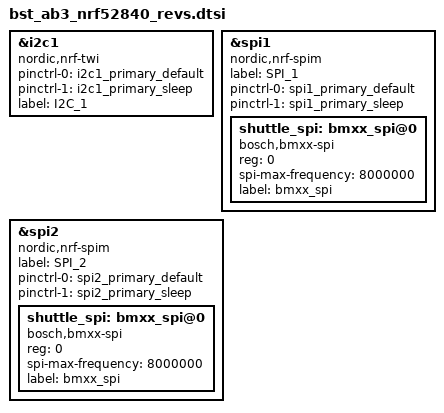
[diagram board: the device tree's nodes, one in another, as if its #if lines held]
/*
 * Copyright (c) 2022 Bosch Sensortec GmbH
 *
 * SPDX-License-Identifier: Apache-2.0
 *
 * Common file for all revisions of DTS for Bosch Sensortec Application Board 3.0
 * This file contains all the variations in one place, and different sections are
 * activated in the corresponding revision overlays.
 *
 * Below is the revision table for reference. Refer the note on Revisions 
 * in bst_ab3_nrf52840.dts for further details.
 * Rev No.		i2c1 					spi1 				spi2
 *  1		primary_i2c_port		disabled			primary_spi_port [DEFAULT]
 *  2		primary_i2c_port		disabled			aux_spi_port	
 *  3		aux_i2c_port			disabled			primary_spi_port	
 *  4		disabled				primary_spi_port	aux_spi_port
 */
#include "bst_ab3_nrf52840-pinctrl.dtsi"

#if defined(BST_AB3_REV1)
	#define I2C1_PRIMARY
	#define SPI1_DISABLED
	#define SPI2_PRIMARY
#elif defined(BST_AB3_REV2)
	#define I2C1_PRIMARY
	#define SPI1_DISABLED
	#define SPI2_AUX
#elif defined(BST_AB3_REV3)
	#define I2C1_AUX
	#define SPI1_DISABLED
	#define SPI2_PRIMARY
#elif defined(BST_AB3_REV4)
	#define I2C1_DISABLED
	#define SPI1_PRIMARY
	#define SPI2_AUX
#else
	#error Unknown BST AB3 Revision	
#endif

#if defined(I2C1_PRIMARY)
	/*i2c1 is used as primary shuttle i2c port*/
	shuttle_i2c: &i2c1 {
		compatible = "nordic,nrf-twi";
		status = "okay";
		//sda-pin = <6>; 
		//scl-pin = <16>;
		pinctrl-0 = <&i2c1_primary_default>;
		pinctrl-1 = <&i2c1_primary_sleep>;
		pinctrl-names = "default", "sleep";
		label = "I2C_1";
	};
#elif defined(I2C1_AUX)
	/*i2c1 is used for auxilliary shuttle i2c port*/
	shuttle_aux_i2c: &i2c1 {
		compatible = "nordic,nrf-twi";
		status = "okay";
		//sda-pin = <13>;  /*GPIO 1 acts as aux i2c SDA*/
		//scl-pin = <14>;  /*GPIO 0 acts as aux i2c SCL*/
		pinctrl-0 = <&i2c1_aux_default>;
		pinctrl-1 = <&i2c1_aux_sleep>;
		label = "I2C_1";
	};
#elif defined(I2C1_DISABLED)
	/*i2c1 is disabled*/
	&i2c1 {
			status = "disabled";
		};
#endif

#if defined(SPI1_PRIMARY)
	/*spi1 is used as primary shuttle spi port*/
	&spi1 {
		compatible = "nordic,nrf-spim";
		status = "okay";
		label = "SPI_1";
		//sck-pin = <16>;
		//mosi-pin = <6>;
		//miso-pin = <15>;
		pinctrl-0 = <&spi1_primary_default>;
		pinctrl-1 = <&spi1_primary_sleep>;
		pinctrl-names = "default", "sleep";
		/*cs-gpios   = <&gpio0 24 GPIO_ACTIVE_LOW>;*/
		/*CS gpio pin is not defined in DTS, as it can be potentially a 
		different pin from the default for some sensors*/
		/*bmxx_spi represents the primary SPI interface of a BST sensor chip mounted on 
		the shuttle board*/
		shuttle_spi: bmxx_spi@0 {
			compatible = "bosch,bmxx-spi";
			reg = <0>;
			spi-max-frequency = <8000000>;
			label = "bmxx_spi";
			status = "okay";
		};

	};
#elif defined(SPI1_DISABLED)
	/*spi1 is disabled*/
	&spi1 {
		status = "disabled";
		label = "SPI_1";
	};
#endif

#if defined(SPI2_PRIMARY)
	/*spi2 is used as primary shuttle spi port*/
	&spi2 {
		compatible = "nordic,nrf-spim";
		status = "okay";
		label = "SPI_2";
		//sck-pin = <16>;
		//mosi-pin = <6>;
		//miso-pin = <15>;
		pinctrl-0 = <&spi2_primary_default>;
		pinctrl-1 = <&spi2_primary_sleep>;
		pinctrl-names = "default", "sleep";
		/*cs-gpios   = <&gpio0 24 GPIO_ACTIVE_LOW>;*/
		/*CS gpio pin is not defined in DTS, as it can be potentially a 
		different pin from the default for some sensors*/
		/*bmxx_spi represents the primary SPI interface of a BST sensor chip mounted on 
		the shuttle board*/
		shuttle_spi: bmxx_spi@0 {
			compatible = "bosch,bmxx-spi";
			reg = <0>;
			spi-max-frequency = <8000000>;
			label = "bmxx_spi";
			status = "okay";
		};
	};
#elif defined(SPI2_AUX)
	/*spi2 is used as auxilliary shuttle spi port*/
	&spi2 {
		compatible = "nordic,nrf-spim";
		status = "okay";
		label = "SPI_2";
		//sck-pin = <34>;  /*P1.02*/
		//mosi-pin = <42>; /*P1.10*/
		//miso-pin = <43>; /*P1.11*/
		pinctrl-0 = <&spi2_aux_default>;
		pinctrl-1 = <&spi2_aux_sleep>;
		pinctrl-names = "default", "sleep";

		/*cs-gpios   = <&gpio1 3 GPIO_ACTIVE_LOW>;*/
		/*CS gpio pin is not defined in DTS, as it can be potentially a 
		different pin from the default for some sensors*/
		/*bmxx_spi represents the auxiliary SPI interface of a BST sensor chip mounted on 
		the shuttle board*/
		shuttle_aux_spi: bmxx_spi@0 {
			compatible = "bosch,bmxx-spi";
			reg = <0>;
			spi-max-frequency = <8000000>;
			label = "bmxx_spi";
			status = "okay";
		};
	};
#endif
